VERSION ""

NS_ :

BS_:

BU_: ACU SCU
VAL_TABLE_ brake_status 1 "lock brake" 0 "unlock brake" ;
VAL_TABLE_ error_clear_instruction 7 "celar remote control signal loss" 6 "clear steer encoder communicate " 5 "clear battery undervoltage fault" 4 "non" 3 "clear back-left motor failure" 2 "clear back-right motor failure" 1 "clear steer communicate failure" 0 "clear all non-critical faults" ;
VAL_TABLE_ control_mode_setting 1 "CAN command control" 0 "standby" ;
VAL_TABLE_ brake_status 1 "brake lock" 0 "brake release" ;
VAL_TABLE_ current_vehicle_status 2 "system exception" 1 "Emergency shutdownd mode" 0 "system ok" ;
VAL_TABLE_ control_mode 2 "remote control" 1 "CAN command control" 0 "standby" ;

BO_ 785 mileage_feedback: 8 SCU
 SG_ rightback_milemeter : 39|32@0- (1,0) [-2147483648|2147483647] "mm" Vector__XXX
 SG_ leftback_milemeter : 7|32@0- (1,0) [-2147483648|2147483647] "mm" Vector__XXX

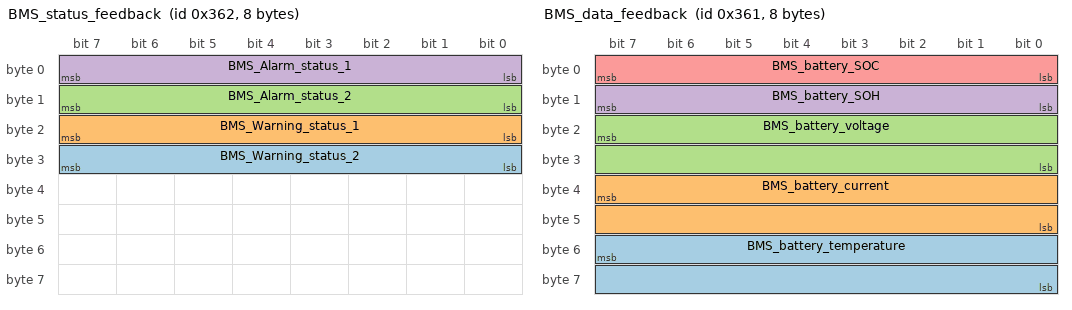
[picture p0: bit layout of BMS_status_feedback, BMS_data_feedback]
BO_ 866 BMS_status_feedback: 8 SCU
 SG_ BMS_Warning_status_2 : 31|8@0+ (1,0) [0|0] "" Vector__XXX
 SG_ BMS_Warning_status_1 : 23|8@0+ (1,0) [0|0] "" Vector__XXX
 SG_ BMS_Alarm_status_2 : 15|8@0+ (1,0) [0|0] "" Vector__XXX
 SG_ BMS_Alarm_status_1 : 7|8@0+ (1,0) [0|0] "" Vector__XXX

BO_ 865 BMS_data_feedback: 8 SCU
 SG_ BMS_battery_temperature : 55|16@0+ (0.1,0) [0|6553.5] "" Vector__XXX
 SG_ BMS_battery_current : 39|16@0+ (0.1,0) [0|6553.5] "A" Vector__XXX
 SG_ BMS_battery_voltage : 23|16@0+ (0.01,0) [0|655.35] "V" Vector__XXX
 SG_ BMS_battery_SOH : 15|8@0+ (1,0) [0|0] "" Vector__XXX
 SG_ BMS_battery_SOC : 7|8@0+ (1,0) [0|255] "" Vector__XXX

BO_ 1082 steering_zore_setting_feedback: 8 SCU
 SG_ set_zero_done_flag : 7|8@0+ (1,0) [0|255] "" Vector__XXX

BO_ 1073 steering_zore_setting: 8 SCU
 SG_ set_zero : 7|8@0+ (1,0) [0|255] "" Vector__XXX

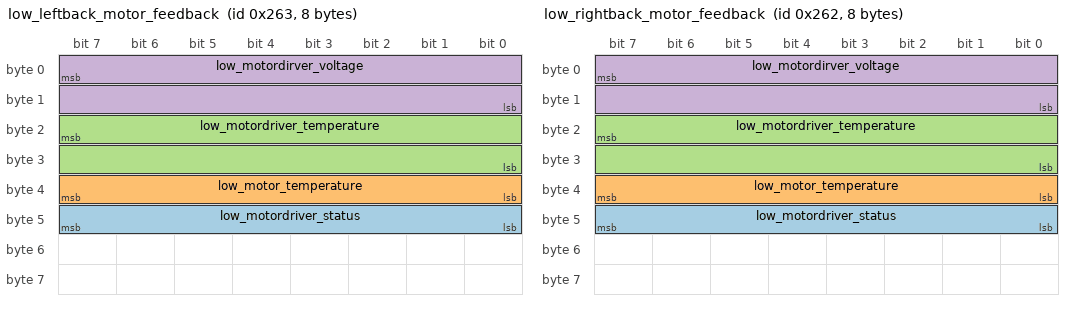
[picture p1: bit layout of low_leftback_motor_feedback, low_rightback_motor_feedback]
BO_ 611 low_leftback_motor_feedback: 8 SCU
 SG_ low_motordriver_status : 47|8@0+ (1,0) [0|255] "" Vector__XXX
 SG_ low_motor_temperature : 39|8@0- (1,0) [-128|127] "" Vector__XXX
 SG_ low_motordriver_temperature : 23|16@0- (1,0) [0|0] "" Vector__XXX
 SG_ low_motordirver_voltage : 7|16@0+ (0.1,0) [0|6553.5] "V" Vector__XXX

BO_ 610 low_rightback_motor_feedback: 8 SCU
 SG_ low_motordriver_status : 47|8@0+ (1,0) [0|255] "" Vector__XXX
 SG_ low_motor_temperature : 39|8@0- (1,0) [-128|127] "" Vector__XXX
 SG_ low_motordriver_temperature : 23|16@0- (1,0) [0|0] "" Vector__XXX
 SG_ low_motordirver_voltage : 7|16@0+ (0.1,0) [0|6553.5] "V" Vector__XXX

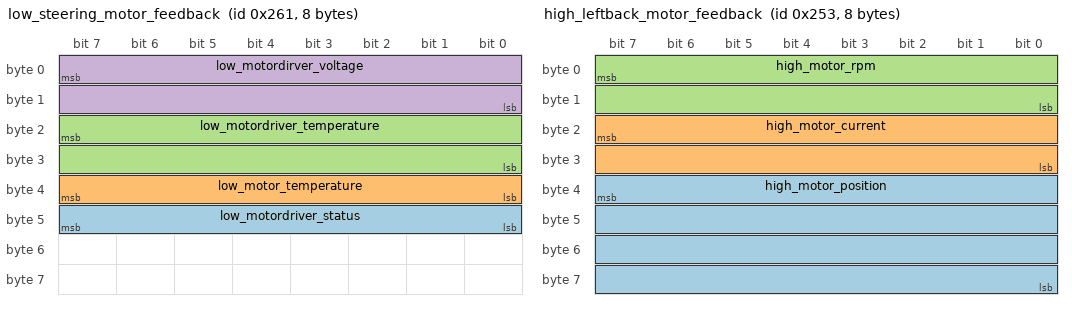
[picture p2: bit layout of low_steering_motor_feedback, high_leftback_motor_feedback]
BO_ 609 low_steering_motor_feedback: 8 SCU
 SG_ low_motordriver_status : 47|8@0+ (1,0) [0|255] "" Vector__XXX
 SG_ low_motor_temperature : 39|8@0- (1,0) [-128|127] "" Vector__XXX
 SG_ low_motordriver_temperature : 23|16@0- (1,0) [0|0] "" Vector__XXX
 SG_ low_motordirver_voltage : 7|16@0+ (0.1,0) [0|6553.5] "V" Vector__XXX

BO_ 595 high_leftback_motor_feedback: 8 SCU
 SG_ high_motor_position : 39|32@0- (1,0) [0|0] "PN" Vector__XXX
 SG_ high_motor_current : 23|16@0- (0.1,0) [-3276.8|3276.7] "A" Vector__XXX
 SG_ high_motor_rpm : 7|16@0- (1,0) [-32768|32767] "RPM" Vector__XXX

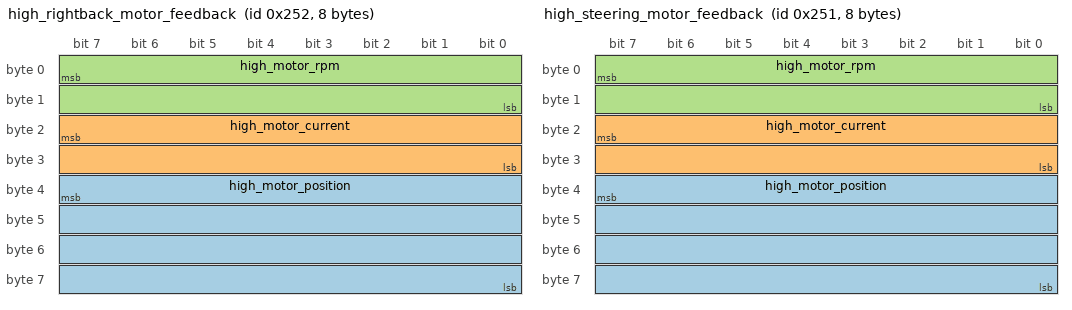
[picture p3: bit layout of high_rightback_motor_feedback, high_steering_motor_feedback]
BO_ 594 high_rightback_motor_feedback: 8 SCU
 SG_ high_motor_position : 39|32@0- (1,0) [0|0] "PN" Vector__XXX
 SG_ high_motor_current : 23|16@0- (0.1,0) [-3276.8|3276.7] "A" Vector__XXX
 SG_ high_motor_rpm : 7|16@0- (1,0) [-32768|32767] "RPM" Vector__XXX

BO_ 593 high_steering_motor_feedback: 8 SCU
 SG_ high_motor_position : 39|32@0- (1,0) [0|0] "PN" Vector__XXX
 SG_ high_motor_current : 23|16@0- (0.1,0) [-3276.8|3276.7] "A" Vector__XXX
 SG_ high_motor_rpm : 7|16@0- (1,0) [-32768|32767] "RPM" Vector__XXX

BO_ 305 brake_control_command: 8 ACU
 SG_ brake_control_command : 7|8@0+ (1,0) [0|255] "" Vector__XXX

BO_ 1089 status_setting: 8 ACU
 SG_ error_clear_instruction : 7|8@0+ (1,0) [0|255] "" Vector__XXX

BO_ 1057 control_mode_setting: 8 ACU
 SG_ control_mode_setting : 7|8@0+ (1,0) [0|255] "" Vector__XXX

BO_ 273 motion_control_instruction: 8 ACU
 SG_ steer_instruction : 55|16@0- (0.001,0) [-32.768|32.767] "rad" Vector__XXX
 SG_ speed_instruction : 7|16@0- (0.001,0) [-32.768|32.767] "m/s" Vector__XXX

BO_ 545 motion_control_feedback: 8 SCU
 SG_ steer : 55|16@0- (0.001,0) [-32.768|32.767] "rad" Vector__XXX
 SG_ speed : 7|16@0- (0.001,0) [-32.768|32.767] "m/s" Vector__XXX

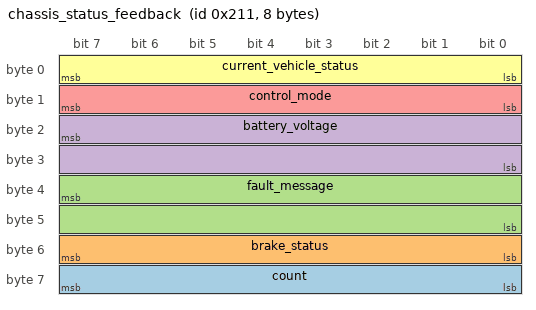
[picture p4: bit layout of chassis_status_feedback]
BO_ 529 chassis_status_feedback: 8 SCU
 SG_ count : 63|8@0+ (1,0) [0|255] "" Vector__XXX
 SG_ brake_status : 55|8@0+ (1,0) [0|0] "" Vector__XXX
 SG_ fault_message : 39|16@0+ (1,0) [0|0] "" Vector__XXX
 SG_ battery_voltage : 23|16@0+ (0.1,0) [0|6553.5] "V" Vector__XXX
 SG_ control_mode : 15|8@0+ (1,0) [0|255] "" Vector__XXX
 SG_ current_vehicle_status : 7|8@0+ (1,0) [0|255] ""  SCU

CM_ BU_ ACU "Apollo node";
CM_ BU_ SCU "vehicle node";
CM_ BO_ 866 "BMS status feedback";
CM_ BO_ 865 "BMS data feedback";
CM_ BO_ 1082 "set the current position to zero if success feedbcak";
CM_ BO_ 1073 "set the current position to zero";
CM_ BO_ 611 "left back motor low speed information feedback";
CM_ BO_ 610 "right back motor low speed information feedback";
CM_ BO_ 609 "steering motor low speed information feedback";
CM_ BO_ 595 "ledt back motor high speed information feedback";
CM_ BO_ 594 "right back motor high speed information feedback";
CM_ BO_ 593 "steering motor high speed information feedback";
BA_DEF_ SG_  "SigType" ENUM  "Default","Range","RangeSigned","ASCII","Discrete","Control","ReferencePGN","DTC","StringDelimiter","StringLength","StringLengthControl","MessageCounter","MessageChecksum";
BA_DEF_ SG_  "GenSigEVName" STRING ;
BA_DEF_ SG_  "GenSigILSupport" ENUM  "No","Yes";
BA_DEF_ SG_  "GenSigSendType" ENUM  "Cyclic","OnWrite","OnWriteWithRepetition","OnChange","OnChangeWithRepetition","IfActive","IfActiveWithRepetition","NoSigSendType";
BA_DEF_ BO_  "GenMsgILSupport" ENUM  "No","Yes";
BA_DEF_ BU_  "NmStationAddress" INT 0 255;
BA_DEF_ BO_  "GenMsgSendType" ENUM  "cyclic","NotUsed","IfActive","NotUsed","NotUsed","NotUsed","NotUsed","NotUsed","noMsgSendType";
BA_DEF_ BO_  "GenMsgRequestable" INT 0 1;
BA_DEF_ BO_  "GenMsgCycleTime" INT 0 3600000;
BA_DEF_  "DBName" STRING ;
BA_DEF_  "BusType" STRING ;
BA_DEF_  "ProtocolType" STRING ;
BA_DEF_ BO_  "VFrameFormat" ENUM  "StandardCAN","ExtendedCAN","reserved","J1939PG";
BA_DEF_DEF_  "SigType" "Default";
BA_DEF_DEF_  "GenSigEVName" "Env@Nodename_@Signame";
BA_DEF_DEF_  "GenSigILSupport" "Yes";
BA_DEF_DEF_  "GenSigSendType" "NoSigSendType";
BA_DEF_DEF_  "GenMsgILSupport" "Yes";
BA_DEF_DEF_  "NmStationAddress" 254;
BA_DEF_DEF_  "GenMsgSendType" "noMsgSendType";
BA_DEF_DEF_  "GenMsgRequestable" 1;
BA_DEF_DEF_  "GenMsgCycleTime" 0;
BA_DEF_DEF_  "DBName" "";
BA_DEF_DEF_  "BusType" "CAN";
BA_DEF_DEF_  "ProtocolType" "J1939";
BA_DEF_DEF_  "VFrameFormat" "J1939PG";
BA_ "DBName" "hunter2";
BA_ "NmStationAddress" BU_ ACU 2;
BA_ "NmStationAddress" BU_ SCU 1;
BA_ "GenMsgCycleTime" BO_ 785 20;
BA_ "VFrameFormat" BO_ 785 0;
BA_ "VFrameFormat" BO_ 866 0;
BA_ "GenMsgCycleTime" BO_ 866 500;
BA_ "GenMsgCycleTime" BO_ 865 500;
BA_ "VFrameFormat" BO_ 865 0;
BA_ "VFrameFormat" BO_ 1082 0;
BA_ "VFrameFormat" BO_ 1073 0;
BA_ "VFrameFormat" BO_ 611 0;
BA_ "GenMsgCycleTime" BO_ 611 100;
BA_ "VFrameFormat" BO_ 610 0;
BA_ "GenMsgCycleTime" BO_ 610 100;
BA_ "VFrameFormat" BO_ 609 0;
BA_ "GenMsgCycleTime" BO_ 609 100;
BA_ "VFrameFormat" BO_ 595 0;
BA_ "GenMsgCycleTime" BO_ 595 20;
BA_ "VFrameFormat" BO_ 594 0;
BA_ "GenMsgCycleTime" BO_ 594 20;
BA_ "VFrameFormat" BO_ 593 0;
BA_ "GenMsgCycleTime" BO_ 593 20;
BA_ "VFrameFormat" BO_ 305 0;
BA_ "VFrameFormat" BO_ 1089 0;
BA_ "VFrameFormat" BO_ 1057 0;
BA_ "VFrameFormat" BO_ 273 0;
BA_ "GenMsgCycleTime" BO_ 273 20;
BA_ "VFrameFormat" BO_ 545 0;
BA_ "GenMsgCycleTime" BO_ 545 20;
BA_ "GenMsgCycleTime" BO_ 529 100;
BA_ "VFrameFormat" BO_ 529 0;
VAL_ 305 brake_control_command 1 "brake lock" 0 "brake release" ;
VAL_ 1089 error_clear_instruction 7 "celar remote control signal loss" 6 "clear steer encoder communicate " 5 "clear battery undervoltage fault" 4 "non" 3 "clear back-left motor failure" 2 "clear back-right motor failure" 1 "clear steer communicate failure" 0 "clear all non-critical faults" ;
VAL_ 1057 control_mode_setting 1 "CAN command control" 0 "standby" ;
VAL_ 529 brake_status 1 "brake lock" 0 "brake release" ;
VAL_ 529 control_mode 2 "remote control" 1 "CAN command control" 0 "standby" ;
VAL_ 529 current_vehicle_status 2 "system exception" 1 "Emergency shutdownd mode" 0 "system ok" ;
